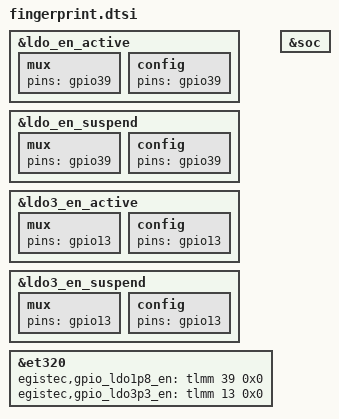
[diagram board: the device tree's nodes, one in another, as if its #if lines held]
#if defined(DEVICE_RHANNAH)
&ldo_en_active {
	mux {
		pins = "gpio39";
	};
	config {
		pins = "gpio39";
	};
};

&ldo_en_suspend {
	mux {
		pins = "gpio39";
	};
	config {
		pins = "gpio39";
	};
};

&ldo3_en_active {
	mux {
		pins = "gpio13";
	};
	config {
		pins = "gpio13";
	};
};

&ldo3_en_suspend {
	mux {
		pins = "gpio13";
	};
	config {
		pins = "gpio13";
	};
};
#elif defined(DEVICE_HANNAH)
&ldo_en_active {
	mux {
		pins = "gpio128";
	};
	config {
		pins = "gpio128";
	};
};

&ldo_en_suspend {
	mux {
		pins = "gpio128";
	};
	config {
		pins = "gpio128";
	};
};

&ldo3_en_active {
	mux {
		pins = "gpio39";
	};
	config {
		pins = "gpio39";
	};
};

&ldo3_en_suspend {
	mux {
		pins = "gpio39";
	};
	config {
		pins = "gpio39";
	};
};
#endif

#ifdef DEVICE_RHANNAH
#include "../common/peripheral/optional/msm8917-moto-common-fps.dtsi"
&et320 {
	egistec,gpio_ldo1p8_en = <&tlmm 39 0x0>;
	egistec,gpio_ldo3p3_en = <&tlmm 13 0x0>;
};
#else
&soc {
    /delete-node/ et320;
	et320: et320{
		compatible = "egistec,et320";
		status = "ok";
		reg = <0>;
		interrupt-parent = <&tlmm>;
		interrupts = <48 0x0>;
		egistec,gpio_irq    = <&tlmm 48 0x1>;
		egistec,gpio_rst    = <&tlmm 127 0x2>;
#ifdef DEVICE_HANNAH
		egistec,gpio_ldo1p8_en = <&tlmm 128 0x0>;
		egistec,gpio_ldo3p3_en = <&tlmm 39 0x0>;
#else
		egistec,gpio_ldo1p8_en = <&tlmm 39 0x0>;
		egistec,gpio_ldo3p3_en = <&tlmm 13 0x0>;
#endif
		pinctrl-names = "default", "suspend";
		pinctrl-0 = <&rst_active &int_active &ldo_en_active &ldo3_en_active>;
		pinctrl-1 = <&rst_suspend &int_suspend &ldo_en_suspend &ldo3_en_suspend>;
	};
};
#endif

&soc {
	/delete-node/ fp_id;
};
